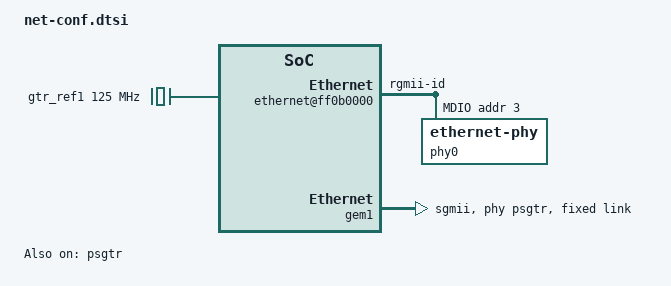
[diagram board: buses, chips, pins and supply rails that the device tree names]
#include <dt-bindings/phy/phy.h>

/ {
    gtr_ref1: gtr-ref1 {
        compatible = "fixed-clock";
        #clock-cells = <0>;
        clock-frequency = <125000000>; /* Set to 125000000 or 156250000 based on your HW */
    };
};

/* Debug ethernet port */
&{/axi/ethernet@ff0b0000} {
    status = "okay";
    phy-mode = "rgmii-id";
    /delete-node/ fixed-link;
    mdio {
        #address-cells = <1>;
        #size-cells = <0>;
        phy0: ethernet-phy@3 {
            reg = <3>;
            device_type = "ethernet-phy";
        };
    };
};

&psgtr {
    status = "okay";
    clocks = <&gtr_ref1>;
    clock-names = "ref1"; 
};


/* SFP GbE */
&gem1 {
    status = "okay";
    phy-mode = "sgmii";
    phys = <&psgtr 1 PHY_TYPE_SGMII 1 1>; 
    phy-names = "gem-phy";
    is-internal-pcspma;
    fixed-link {
        speed = <1000>;
        full-duplex;
    };
};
